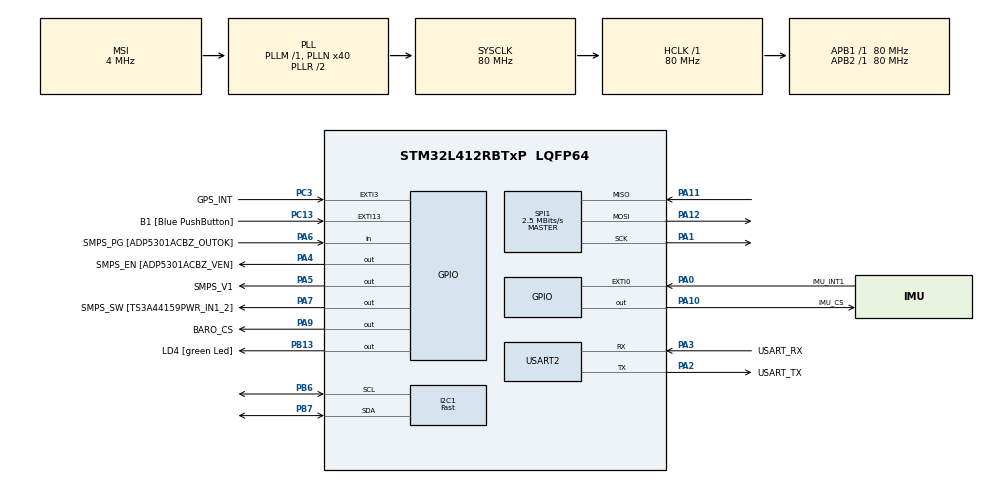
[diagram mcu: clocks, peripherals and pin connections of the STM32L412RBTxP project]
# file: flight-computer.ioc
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Dma.I2C1_RX.2.Direction=DMA_PERIPH_TO_MEMORY
Dma.I2C1_RX.2.Instance=DMA1_Channel7
Dma.I2C1_RX.2.MemDataAlignment=DMA_MDATAALIGN_BYTE
Dma.I2C1_RX.2.MemInc=DMA_MINC_ENABLE
Dma.I2C1_RX.2.Mode=DMA_NORMAL
Dma.I2C1_RX.2.PeriphDataAlignment=DMA_PDATAALIGN_BYTE
Dma.I2C1_RX.2.PeriphInc=DMA_PINC_DISABLE
Dma.I2C1_RX.2.Priority=DMA_PRIORITY_LOW
Dma.I2C1_TX.3.Direction=DMA_MEMORY_TO_PERIPH
Dma.I2C1_TX.3.Instance=DMA1_Channel6
Dma.I2C1_TX.3.MemDataAlignment=DMA_MDATAALIGN_BYTE
Dma.I2C1_TX.3.MemInc=DMA_MINC_ENABLE
Dma.I2C1_TX.3.Mode=DMA_NORMAL
Dma.I2C1_TX.3.PeriphDataAlignment=DMA_PDATAALIGN_BYTE
Dma.I2C1_TX.3.PeriphInc=DMA_PINC_DISABLE
Dma.I2C1_TX.3.Priority=DMA_PRIORITY_LOW
Dma.Request0=SPI1_RX
Dma.Request1=SPI1_TX
Dma.Request2=I2C1_RX
Dma.Request3=I2C1_TX
Dma.SPI1_RX.0.Direction=DMA_PERIPH_TO_MEMORY
Dma.SPI1_RX.0.Instance=DMA1_Channel2
Dma.SPI1_RX.0.MemDataAlignment=DMA_MDATAALIGN_BYTE
Dma.SPI1_RX.0.MemInc=DMA_MINC_ENABLE
Dma.SPI1_RX.0.Mode=DMA_NORMAL
Dma.SPI1_RX.0.PeriphDataAlignment=DMA_PDATAALIGN_BYTE
Dma.SPI1_RX.0.PeriphInc=DMA_PINC_DISABLE
Dma.SPI1_RX.0.Priority=DMA_PRIORITY_LOW
Dma.SPI1_TX.1.Direction=DMA_MEMORY_TO_PERIPH
Dma.SPI1_TX.1.Instance=DMA1_Channel3
Dma.SPI1_TX.1.MemDataAlignment=DMA_MDATAALIGN_BYTE
Dma.SPI1_TX.1.MemInc=DMA_MINC_ENABLE
Dma.SPI1_TX.1.Mode=DMA_NORMAL
Dma.SPI1_TX.1.PeriphDataAlignment=DMA_PDATAALIGN_BYTE
Dma.SPI1_TX.1.PeriphInc=DMA_PINC_DISABLE
Dma.SPI1_TX.1.Priority=DMA_PRIORITY_LOW
FREERTOS.Tasks01=SPI1TaskHandler,54,1024,spi1TaskHandler,As weak,NULL,Static,SPI1TaskHandlerBuffer,SPI1TaskHandlerControlBlock;BarometerTask,55,128,barometerTask,As external,NULL,Static,BarometerTaskBuffer,BarometerTaskControlBlock;I2CTaskHandler,54,1024,i2c1TaskHandler,As weak,NULL,Static,I2CTaskHandlerBuffer,I2CTaskHandlerControlBlock
I2C1.I2C_Speed_Mode=I2C_Fast
I2C1.Timing=0x00F12981
Mcu.Family=STM32L4
Mcu.Name=STM32L412RBTxP
Mcu.Package=LQFP64
NVIC.DMA1_Channel2_IRQn=true\:5\:0\:false\:false\:true\:true\:false\:true\:true
NVIC.DMA1_Channel3_IRQn=true\:5\:0\:false\:false\:true\:true\:false\:true\:true
NVIC.DMA1_Channel6_IRQn=true\:5\:0\:false\:false\:true\:true\:false\:true\:true
NVIC.DMA1_Channel7_IRQn=true\:5\:0\:false\:false\:true\:true\:false\:true\:true
NVIC.EXTI0_IRQn=true\:5\:0\:false\:false\:true\:true\:true\:true\:true
NVIC.EXTI15_10_IRQn=true\:5\:0\:false\:false\:true\:true\:true\:true\:true
NVIC.EXTI3_IRQn=true\:5\:0\:false\:false\:true\:true\:true\:true\:true
NVIC.I2C1_ER_IRQn=true\:5\:0\:false\:false\:true\:true\:true\:true\:true
NVIC.I2C1_EV_IRQn=true\:5\:0\:false\:false\:true\:true\:true\:true\:true
NVIC.PriorityGroup=NVIC_PRIORITYGROUP_4
NVIC.SPI1_IRQn=true\:5\:0\:false\:false\:true\:true\:true\:true\:true
NVIC.TIM1_UP_TIM16_IRQn=true\:15\:0\:false\:false\:true\:false\:false\:true\:true
NVIC.TimeBase=TIM1_UP_TIM16_IRQn
NVIC.TimeBaseIP=TIM1
PA0.GPIO_Label=IMU_INT1
PA0.GPIO_ModeDefaultEXTI=GPIO_MODE_IT_RISING
PA0.Signal=GPXTI0
PA1.GPIO_Speed=GPIO_SPEED_FREQ_VERY_HIGH
PA1.Mode=Full_Duplex_Master
PA1.Signal=SPI1_SCK
PA10.GPIO_Label=IMU_CS
PA10.GPIO_PuPd=GPIO_NOPULL
PA10.GPIO_Speed=GPIO_SPEED_FREQ_MEDIUM
PA10.PinState=GPIO_PIN_SET
PA10.Signal=GPIO_Output
PA11.GPIO_Speed=GPIO_SPEED_FREQ_VERY_HIGH
PA11.Mode=Full_Duplex_Master
PA11.Signal=SPI1_MISO
PA12.GPIO_Speed=GPIO_SPEED_FREQ_VERY_HIGH
PA12.Mode=Full_Duplex_Master
PA12.Signal=SPI1_MOSI
PA13\ (JTMS/SWDIO).GPIO_Label=TMS
PA13\ (JTMS/SWDIO).Mode=Serial_Wire
PA13\ (JTMS/SWDIO).Signal=SYS_JTMS-SWDIO
PA14\ (JTCK/SWCLK).GPIO_Label=TCK
PA14\ (JTCK/SWCLK).Mode=Serial_Wire
PA14\ (JTCK/SWCLK).Signal=SYS_JTCK-SWCLK
PA2.GPIO_Label=USART_TX
PA2.GPIO_PuPd=GPIO_NOPULL
PA2.GPIO_Speed=GPIO_SPEED_FREQ_VERY_HIGH
PA2.Mode=Asynchronous
PA2.Signal=USART2_TX
PA3.GPIO_Label=USART_RX
PA3.GPIO_PuPd=GPIO_NOPULL
PA3.GPIO_Speed=GPIO_SPEED_FREQ_VERY_HIGH
PA3.Mode=Asynchronous
PA3.Signal=USART2_RX
PA4.GPIO_Label=SMPS_EN [ADP5301ACBZ_VEN]
PA4.Signal=GPIO_Output
PA5.GPIO_Label=SMPS_V1
PA5.GPIO_ModeDefaultOutputPP=GPIO_MODE_OUTPUT_PP
PA5.GPIO_PuPd=GPIO_NOPULL
PA5.GPIO_Speed=GPIO_SPEED_FREQ_LOW
PA5.Signal=GPIO_Output
PA6.GPIO_Label=SMPS_PG [ADP5301ACBZ_OUTOK]
PA6.GPIO_PuPd=GPIO_PULLUP
PA6.Signal=GPIO_Input
PA7.GPIO_Label=SMPS_SW [TS3A44159PWR_IN1_2]
PA7.Signal=GPIO_Output
PA9.GPIO_Label=BARO_CS
PA9.GPIO_Speed=GPIO_SPEED_FREQ_MEDIUM
PA9.PinState=GPIO_PIN_SET
PA9.Signal=GPIO_Output
PB13.GPIO_Label=LD4 [green Led]
PB13.Signal=GPIO_Output
PB3\ (JTDO/TRACESWO).GPIO_Label=SWO
PB3\ (JTDO/TRACESWO).Signal=SYS_JTDO-SWO
PB6.Mode=I2C
PB6.Signal=I2C1_SCL
PB7.Mode=I2C
PB7.Signal=I2C1_SDA
PC13.GPIO_Label=B1 [Blue PushButton]
PC13.GPIO_ModeDefaultEXTI=GPIO_MODE_IT_FALLING
PC13.GPIO_PuPd=GPIO_NOPULL
PC13.Signal=GPXTI13
PC14-OSC32_IN\ (PC14).Mode=LSE-External-Oscillator
PC14-OSC32_IN\ (PC14).Signal=RCC_OSC32_IN
PC15-OSC32_OUT\ (PC15).Mode=LSE-External-Oscillator
PC15-OSC32_OUT\ (PC15).Signal=RCC_OSC32_OUT
PC3.GPIO_Label=GPS_INT
PC3.Signal=GPXTI3
PH0-OSC_IN\ (PH0).GPIO_Label=MCO
PH0-OSC_IN\ (PH0).Mode=HSE-External-Clock-Source
PH0-OSC_IN\ (PH0).Signal=RCC_OSC_IN
PH1-OSC_OUT\ (PH1).Signal=RCC_OSC_OUT
ProjectManager.HeapSize=0x200
ProjectManager.StackSize=0x400
ProjectManager.TargetToolchain=CMake
RCC.ADCFreq_Value=80000000
RCC.AHBFreq_Value=80000000
RCC.APB1Freq_Value=80000000
RCC.APB1TimFreq_Value=80000000
RCC.APB2Freq_Value=80000000
RCC.APB2TimFreq_Value=80000000
RCC.CortexFreq_Value=80000000
RCC.FLatency=FLASH_LATENCY_4
RCC.HCLKFreq_Value=80000000
RCC.HSE_VALUE=8000000
RCC.HSI48_VALUE=48000000
RCC.HSICalibrationValue=64
RCC.HSI_VALUE=16000000
RCC.MSIAutoCalibration=DISABLED
RCC.MSI_VALUE=4000000
RCC.PLLN=40
RCC.PREFETCH_ENABLE=1
RCC.SYSCLKFreq_VALUE=80000000
RCC.SYSCLKSource=RCC_SYSCLKSOURCE_PLLCLK
RCC.USBFreq_Value=4000000
RCC.VCOOutputFreq_Value=160000000
SPI1.BaudRatePrescaler=SPI_BAUDRATEPRESCALER_32
SPI1.CLKPhase=SPI_PHASE_1EDGE
SPI1.CLKPolarity=SPI_POLARITY_LOW
SPI1.CalculateBaudRate=2.5 MBits/s
SPI1.DataSize=SPI_DATASIZE_8BIT
SPI1.Direction=SPI_DIRECTION_2LINES
SPI1.Mode=SPI_MODE_MASTER
SPI1.VirtualType=VM_MASTER
USART2.VirtualMode-Asynchronous=VM_ASYNC
VP_FREERTOS_VS_CMSIS_V2.Mode=CMSIS_V2
VP_SYS_VS_tim1.Mode=TIM1
board=NUCLEO-L412RB-P

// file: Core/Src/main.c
/* USER CODE BEGIN Header */
/**
 ******************************************************************************
 * @file           : main.c
 * @brief          : Main program body
 ******************************************************************************
 * @attention
 *
 * Copyright (c) 2026 STMicroelectronics.
 * All rights reserved.
 *
 * This software is licensed under terms that can be found in the LICENSE file
 * in the root directory of this software component.
 * If no LICENSE file comes with this software, it is provided AS-IS.
 *
 ******************************************************************************
 */
/* USER CODE END Header */
#include "main.h"
#include "cmsis_os.h"

/* USER CODE BEGIN Includes */
#include "stm32l4xx_hal.h"
/* USER CODE END Includes */

typedef StaticTask_t osStaticThreadDef_t;

I2C_HandleTypeDef hi2c1;
DMA_HandleTypeDef hdma_i2c1_rx;
DMA_HandleTypeDef hdma_i2c1_tx;

SPI_HandleTypeDef hspi1;
DMA_HandleTypeDef hdma_spi1_rx;
DMA_HandleTypeDef hdma_spi1_tx;

UART_HandleTypeDef huart2;

/* Definitions for SPI1TaskHandler */
osThreadId_t SPI1TaskHandlerHandle;
uint32_t SPI1TaskHandlerBuffer[ 1024 ];
osStaticThreadDef_t SPI1TaskHandlerControlBlock;
const osThreadAttr_t SPI1TaskHandler_attributes = {
  .name = "SPI1TaskHandler",
  .cb_mem = &SPI1TaskHandlerControlBlock,
  .cb_size = sizeof(SPI1TaskHandlerControlBlock),
  .stack_mem = &SPI1TaskHandlerBuffer[0],
  .stack_size = sizeof(SPI1TaskHandlerBuffer),
  .priority = (osPriority_t) osPriorityRealtime6,
};
/* Definitions for BarometerTask */
osThreadId_t BarometerTaskHandle;
uint32_t BarometerTaskBuffer[ 128 ];
osStaticThreadDef_t BarometerTaskControlBlock;
const osThreadAttr_t BarometerTask_attributes = {
  .name = "BarometerTask",
  .cb_mem = &BarometerTaskControlBlock,
  .cb_size = sizeof(BarometerTaskControlBlock),
  .stack_mem = &BarometerTaskBuffer[0],
  .stack_size = sizeof(BarometerTaskBuffer),
  .priority = (osPriority_t) osPriorityRealtime7,
};
/* Definitions for I2CTaskHandler */
osThreadId_t I2CTaskHandlerHandle;
uint32_t I2CTaskHandlerBuffer[ 1024 ];
osStaticThreadDef_t I2CTaskHandlerControlBlock;
const osThreadAttr_t I2CTaskHandler_attributes = {
  .name = "I2CTaskHandler",
  .cb_mem = &I2CTaskHandlerControlBlock,
  .cb_size = sizeof(I2CTaskHandlerControlBlock),
  .stack_mem = &I2CTaskHandlerBuffer[0],
  .stack_size = sizeof(I2CTaskHandlerBuffer),
  .priority = (osPriority_t) osPriorityRealtime6,
};

void SystemClock_Config(void);
static void MX_GPIO_Init(void);
static void MX_DMA_Init(void);
static void MX_USART2_UART_Init(void);
static void MX_SPI1_Init(void);
static void MX_I2C1_Init(void);
void spi1TaskHandler(void *argument);
extern void barometerTask(void *argument);
void i2c1TaskHandler(void *argument);

int main(void)
{

  /* MCU Configuration--------------------------------------------------------*/

  /* Reset of all peripherals, Initializes the Flash interface and the Systick. */
  HAL_Init();

  /* Configure the system clock */
  SystemClock_Config();

  /* Initialize all configured peripherals */
  MX_GPIO_Init();
  MX_DMA_Init();
  MX_USART2_UART_Init();
  MX_SPI1_Init();
  MX_I2C1_Init();

  /* Init scheduler */
  osKernelInitialize();

  /* Create the thread(s) */
  /* creation of SPI1TaskHandler */
  SPI1TaskHandlerHandle = osThreadNew(spi1TaskHandler, NULL, &SPI1TaskHandler_attributes);

  /* creation of BarometerTask */
  BarometerTaskHandle = osThreadNew(barometerTask, NULL, &BarometerTask_attributes);

  /* creation of I2CTaskHandler */
  I2CTaskHandlerHandle = osThreadNew(i2c1TaskHandler, NULL, &I2CTaskHandler_attributes);

  /* Start scheduler */
  osKernelStart();

  /* We should never get here as control is now taken by the scheduler */

  /* Infinite loop */
    while (1) {

    }
}

void SystemClock_Config(void)
{
  RCC_OscInitTypeDef RCC_OscInitStruct = {0};
  RCC_ClkInitTypeDef RCC_ClkInitStruct = {0};

  /** Configure the main internal regulator output voltage
  */
  if (HAL_PWREx_ControlVoltageScaling(PWR_REGULATOR_VOLTAGE_SCALE1) != HAL_OK)
  {
    Error_Handler();
  }

  /** Initializes the RCC Oscillators according to the specified parameters
  * in the RCC_OscInitTypeDef structure.
  */
  RCC_OscInitStruct.OscillatorType = RCC_OSCILLATORTYPE_MSI;
  RCC_OscInitStruct.MSIState = RCC_MSI_ON;
  RCC_OscInitStruct.MSICalibrationValue = 0;
  RCC_OscInitStruct.MSIClockRange = RCC_MSIRANGE_6;
  RCC_OscInitStruct.PLL.PLLState = RCC_PLL_ON;
  RCC_OscInitStruct.PLL.PLLSource = RCC_PLLSOURCE_MSI;
  RCC_OscInitStruct.PLL.PLLM = 1;
  RCC_OscInitStruct.PLL.PLLN = 40;
  RCC_OscInitStruct.PLL.PLLQ = RCC_PLLQ_DIV2;
  RCC_OscInitStruct.PLL.PLLR = RCC_PLLR_DIV2;
  if (HAL_RCC_OscConfig(&RCC_OscInitStruct) != HAL_OK)
  {
    Error_Handler();
  }

  /** Initializes the CPU, AHB and APB buses clocks
  */
  RCC_ClkInitStruct.ClockType = RCC_CLOCKTYPE_HCLK|RCC_CLOCKTYPE_SYSCLK
                              |RCC_CLOCKTYPE_PCLK1|RCC_CLOCKTYPE_PCLK2;
  RCC_ClkInitStruct.SYSCLKSource = RCC_SYSCLKSOURCE_PLLCLK;
  RCC_ClkInitStruct.AHBCLKDivider = RCC_SYSCLK_DIV1;
  RCC_ClkInitStruct.APB1CLKDivider = RCC_HCLK_DIV1;
  RCC_ClkInitStruct.APB2CLKDivider = RCC_HCLK_DIV1;

  if (HAL_RCC_ClockConfig(&RCC_ClkInitStruct, FLASH_LATENCY_4) != HAL_OK)
  {
    Error_Handler();
  }
}

static void MX_I2C1_Init(void)
{

  hi2c1.Instance = I2C1;
  hi2c1.Init.Timing = 0x00F12981;
  hi2c1.Init.OwnAddress1 = 0;
  hi2c1.Init.AddressingMode = I2C_ADDRESSINGMODE_7BIT;
  hi2c1.Init.DualAddressMode = I2C_DUALADDRESS_DISABLE;
  hi2c1.Init.OwnAddress2 = 0;
  hi2c1.Init.OwnAddress2Masks = I2C_OA2_NOMASK;
  hi2c1.Init.GeneralCallMode = I2C_GENERALCALL_DISABLE;
  hi2c1.Init.NoStretchMode = I2C_NOSTRETCH_DISABLE;
  if (HAL_I2C_Init(&hi2c1) != HAL_OK)
  {
    Error_Handler();
  }

  /** Configure Analogue filter
  */
  if (HAL_I2CEx_ConfigAnalogFilter(&hi2c1, I2C_ANALOGFILTER_ENABLE) != HAL_OK)
  {
    Error_Handler();
  }

  /** Configure Digital filter
  */
  if (HAL_I2CEx_ConfigDigitalFilter(&hi2c1, 0) != HAL_OK)
  {
    Error_Handler();
  }

}

static void MX_SPI1_Init(void)
{

  /* SPI1 parameter configuration*/
  hspi1.Instance = SPI1;
  hspi1.Init.Mode = SPI_MODE_MASTER;
  hspi1.Init.Direction = SPI_DIRECTION_2LINES;
  hspi1.Init.DataSize = SPI_DATASIZE_8BIT;
  hspi1.Init.CLKPolarity = SPI_POLARITY_LOW;
  hspi1.Init.CLKPhase = SPI_PHASE_1EDGE;
  hspi1.Init.NSS = SPI_NSS_SOFT;
  hspi1.Init.BaudRatePrescaler = SPI_BAUDRATEPRESCALER_32;
  hspi1.Init.FirstBit = SPI_FIRSTBIT_MSB;
  hspi1.Init.TIMode = SPI_TIMODE_DISABLE;
  hspi1.Init.CRCCalculation = SPI_CRCCALCULATION_DISABLE;
  hspi1.Init.CRCPolynomial = 7;
  hspi1.Init.CRCLength = SPI_CRC_LENGTH_DATASIZE;
  hspi1.Init.NSSPMode = SPI_NSS_PULSE_ENABLE;
  if (HAL_SPI_Init(&hspi1) != HAL_OK)
  {
    Error_Handler();
  }

}

static void MX_USART2_UART_Init(void)
{

  huart2.Instance = USART2;
  huart2.Init.BaudRate = 115200;
  huart2.Init.WordLength = UART_WORDLENGTH_8B;
  huart2.Init.StopBits = UART_STOPBITS_1;
  huart2.Init.Parity = UART_PARITY_NONE;
  huart2.Init.Mode = UART_MODE_TX_RX;
  huart2.Init.HwFlowCtl = UART_HWCONTROL_NONE;
  huart2.Init.OverSampling = UART_OVERSAMPLING_16;
  huart2.Init.OneBitSampling = UART_ONE_BIT_SAMPLE_DISABLE;
  huart2.AdvancedInit.AdvFeatureInit = UART_ADVFEATURE_NO_INIT;
  if (HAL_UART_Init(&huart2) != HAL_OK)
  {
    Error_Handler();
  }

}

static void MX_DMA_Init(void)
{

  /* DMA controller clock enable */
  __HAL_RCC_DMA1_CLK_ENABLE();

  /* DMA interrupt init */
  /* DMA1_Channel2_IRQn interrupt configuration */
  HAL_NVIC_SetPriority(DMA1_Channel2_IRQn, 5, 0);
  HAL_NVIC_EnableIRQ(DMA1_Channel2_IRQn);
  /* DMA1_Channel3_IRQn interrupt configuration */
  HAL_NVIC_SetPriority(DMA1_Channel3_IRQn, 5, 0);
  HAL_NVIC_EnableIRQ(DMA1_Channel3_IRQn);
  /* DMA1_Channel6_IRQn interrupt configuration */
  HAL_NVIC_SetPriority(DMA1_Channel6_IRQn, 5, 0);
  HAL_NVIC_EnableIRQ(DMA1_Channel6_IRQn);
  /* DMA1_Channel7_IRQn interrupt configuration */
  HAL_NVIC_SetPriority(DMA1_Channel7_IRQn, 5, 0);
  HAL_NVIC_EnableIRQ(DMA1_Channel7_IRQn);

}

static void MX_GPIO_Init(void)
{
  GPIO_InitTypeDef GPIO_InitStruct = {0};

  /* GPIO Ports Clock Enable */
  __HAL_RCC_GPIOC_CLK_ENABLE();
  __HAL_RCC_GPIOH_CLK_ENABLE();
  __HAL_RCC_GPIOA_CLK_ENABLE();
  __HAL_RCC_GPIOB_CLK_ENABLE();

  /*Configure GPIO pin Output Level */
  HAL_GPIO_WritePin(GPIOA, SMPS_EN_Pin|SMPS_V1_Pin|SMPS_SW_Pin, GPIO_PIN_RESET);

  /*Configure GPIO pin Output Level */
  HAL_GPIO_WritePin(LD4_GPIO_Port, LD4_Pin, GPIO_PIN_RESET);

  /*Configure GPIO pin Output Level */
  HAL_GPIO_WritePin(GPIOA, BARO_CS_Pin|IMU_CS_Pin, GPIO_PIN_SET);

  /*Configure GPIO pin : B1_Pin */
  GPIO_InitStruct.Pin = B1_Pin;
  GPIO_InitStruct.Mode = GPIO_MODE_IT_FALLING;
  GPIO_InitStruct.Pull = GPIO_NOPULL;
  HAL_GPIO_Init(B1_GPIO_Port, &GPIO_InitStruct);

  /*Configure GPIO pin : GPS_INT_Pin */
  GPIO_InitStruct.Pin = GPS_INT_Pin;
  GPIO_InitStruct.Mode = GPIO_MODE_IT_RISING;
  GPIO_InitStruct.Pull = GPIO_NOPULL;
  HAL_GPIO_Init(GPS_INT_GPIO_Port, &GPIO_InitStruct);

  /*Configure GPIO pin : IMU_INT1_Pin */
  GPIO_InitStruct.Pin = IMU_INT1_Pin;
  GPIO_InitStruct.Mode = GPIO_MODE_IT_RISING;
  GPIO_InitStruct.Pull = GPIO_NOPULL;
  HAL_GPIO_Init(IMU_INT1_GPIO_Port, &GPIO_InitStruct);

  /*Configure GPIO pins : SMPS_EN_Pin SMPS_V1_Pin SMPS_SW_Pin */
  GPIO_InitStruct.Pin = SMPS_EN_Pin|SMPS_V1_Pin|SMPS_SW_Pin;
  GPIO_InitStruct.Mode = GPIO_MODE_OUTPUT_PP;
  GPIO_InitStruct.Pull = GPIO_NOPULL;
  GPIO_InitStruct.Speed = GPIO_SPEED_FREQ_LOW;
  HAL_GPIO_Init(GPIOA, &GPIO_InitStruct);

  /*Configure GPIO pin : SMPS_PG_Pin */
  GPIO_InitStruct.Pin = SMPS_PG_Pin;
  GPIO_InitStruct.Mode = GPIO_MODE_INPUT;
  GPIO_InitStruct.Pull = GPIO_PULLUP;
  HAL_GPIO_Init(SMPS_PG_GPIO_Port, &GPIO_InitStruct);

  /*Configure GPIO pin : LD4_Pin */
  GPIO_InitStruct.Pin = LD4_Pin;
  GPIO_InitStruct.Mode = GPIO_MODE_OUTPUT_PP;
  GPIO_InitStruct.Pull = GPIO_NOPULL;
  GPIO_InitStruct.Speed = GPIO_SPEED_FREQ_LOW;
  HAL_GPIO_Init(LD4_GPIO_Port, &GPIO_InitStruct);

  /*Configure GPIO pins : BARO_CS_Pin IMU_CS_Pin */
  GPIO_InitStruct.Pin = BARO_CS_Pin|IMU_CS_Pin;
  GPIO_InitStruct.Mode = GPIO_MODE_OUTPUT_PP;
  GPIO_InitStruct.Pull = GPIO_NOPULL;
  GPIO_InitStruct.Speed = GPIO_SPEED_FREQ_MEDIUM;
  HAL_GPIO_Init(GPIOA, &GPIO_InitStruct);

  /* EXTI interrupt init*/
  HAL_NVIC_SetPriority(EXTI0_IRQn, 5, 0);
  HAL_NVIC_EnableIRQ(EXTI0_IRQn);

  HAL_NVIC_SetPriority(EXTI3_IRQn, 5, 0);
  HAL_NVIC_EnableIRQ(EXTI3_IRQn);

  HAL_NVIC_SetPriority(EXTI15_10_IRQn, 5, 0);
  HAL_NVIC_EnableIRQ(EXTI15_10_IRQn);

}

__weak void spi1TaskHandler(void *argument)
{
    for (;;) {
        osDelay(1);
    }
}

__weak void i2c1TaskHandler(void *argument)
{
    for (;;) {
        osDelay(1);
    }
}

void HAL_TIM_PeriodElapsedCallback(TIM_HandleTypeDef *htim)
{
  if (htim->Instance == TIM1)
  {
    HAL_IncTick();
  }
}

void Error_Handler(void)
{
  /* USER CODE BEGIN Error_Handler_Debug */
    /* User can add his own implementation to report the HAL error return state
     */
    __disable_irq();
    while (1) {
    }
  /* USER CODE END Error_Handler_Debug */
}
#ifdef USE_FULL_ASSERT
/**
  * @brief  Reports the name of the source file and the source line number
  *         where the assert_param error has occurred.
  * @param  file: pointer to the source file name
  * @param  line: assert_param error line source number
  * @retval None
  */
void assert_failed(uint8_t *file, uint32_t line)
{
  /* USER CODE BEGIN 6 */
    /* User can add his own implementation to report the file name and line
       number, ex: printf("Wrong parameters value: file %s on line %d\r\n",
       file, line) */
  /* USER CODE END 6 */
}
#endif /* USE_FULL_ASSERT */
